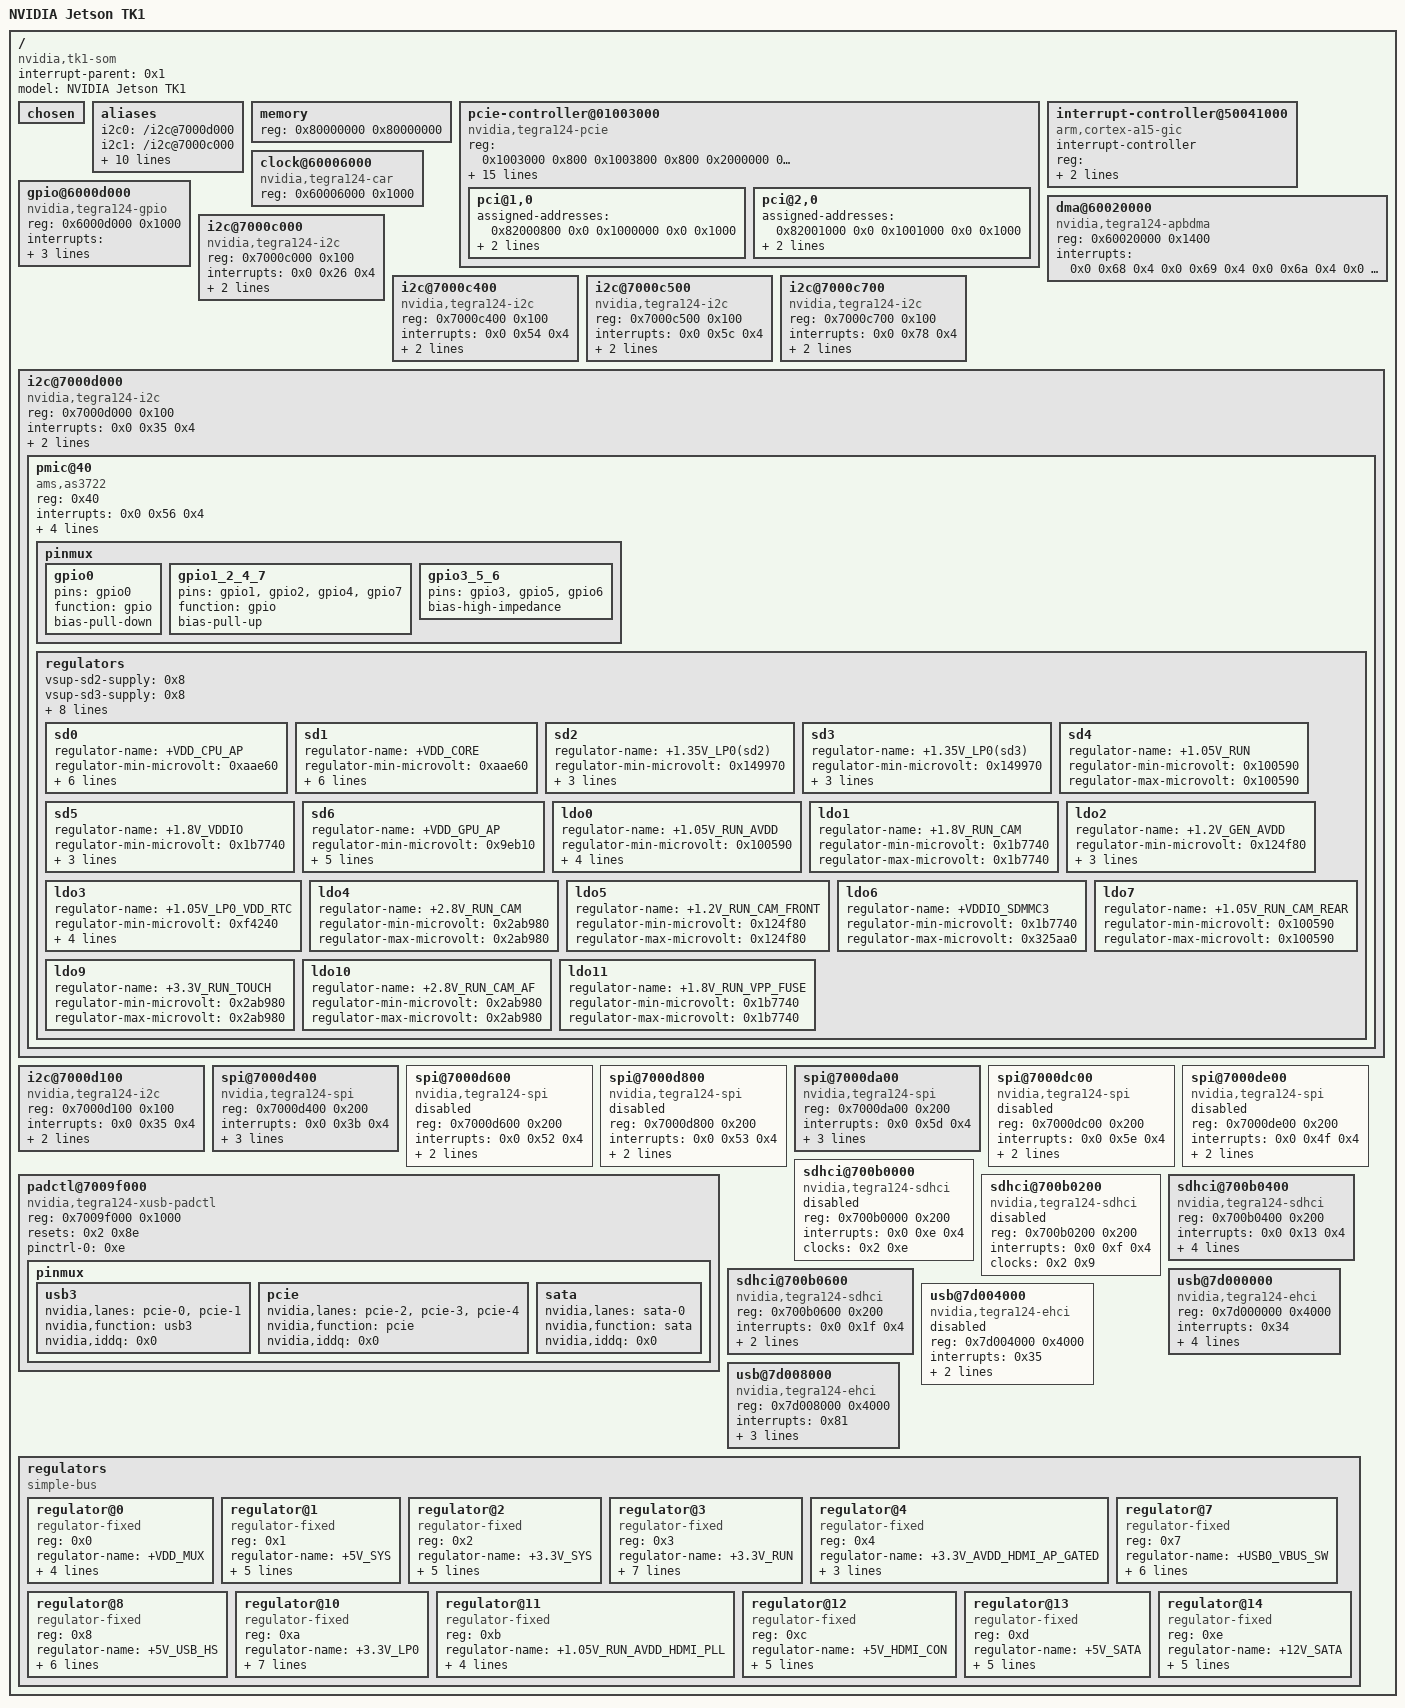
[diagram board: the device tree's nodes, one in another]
/dts-v1/;

/ {
	#address-cells = <0x1>;
	#size-cells = <0x1>;
	compatible = "nvidia,tk1-som", "nvidia,tegra124";
	interrupt-parent = <0x1>;
	model = "NVIDIA Jetson TK1";

	chosen {
	};

	aliases {
		i2c0 = "/i2c@7000d000";
		i2c1 = "/i2c@7000c000";
		i2c2 = "/i2c@7000c400";
		i2c3 = "/i2c@7000c500";
		i2c4 = "/i2c@7000c700";
		i2c5 = "/i2c@7000d100";
		sdhci0 = "/sdhci@700b0600";
		sdhci1 = "/sdhci@700b0400";
		spi0 = "/spi@7000d400";
		spi1 = "/spi@7000da00";
		usb0 = "/usb@7d000000";
		usb1 = "/usb@7d008000";
	};

	memory {
		device_type = "memory";
		reg = <0x80000000 0x80000000>;
	};

	pcie-controller@01003000 {
		compatible = "nvidia,tegra124-pcie";
		device_type = "pci";
		reg = <0x1003000 0x800 0x1003800 0x800 0x2000000 0x10000000>;
		reg-names = "pads", "afi", "cs";
		interrupts = <0x0 0x62 0x4 0x0 0x63 0x4>;
		interrupt-names = "intr", "msi";
		#interrupt-cells = <0x1>;
		interrupt-map-mask = <0x0 0x0 0x0 0x0>;
		interrupt-map = <0x0 0x0 0x0 0x0 0x1 0x0 0x62 0x4>;
		bus-range = <0x0 0xff>;
		#address-cells = <0x3>;
		#size-cells = <0x2>;
		ranges = <0x82000000 0x0 0x1000000 0x1000000 0x0 0x1000 0x82000000 0x0 0x1001000 0x1001000 0x0 0x1000 0x81000000 0x0 0x0 0x12000000 0x0 0x10000 0x82000000 0x0 0x13000000 0x13000000 0x0 0xd000000 0xc2000000 0x0 0x20000000 0x20000000 0x0 0x20000000>;
		clocks = <0x2 0x46 0x2 0x48 0x2 0xe7 0x2 0x10c>;
		clock-names = "pex", "afi", "pll_e", "cml";
		resets = <0x2 0x46 0x2 0x48 0x2 0x4a>;
		reset-names = "pex", "afi", "pcie_x";
		status = "okay";
		phys = <0x3 0x0>;
		phy-names = "pcie";
		avddio-pex-supply = <0x4>;
		vddio-pex-supply = <0x4>;
		avdd-pex-pll-supply = <0x4>;
		hvdd-pex-supply = <0x5>;
		hvdd-pex-plle-supply = <0x5>;
		vddio-pex-ctl-supply = <0x5>;
		avdd-plle-supply = <0x6>;

		pci@1,0 {
			device_type = "pci";
			assigned-addresses = <0x82000800 0x0 0x1000000 0x0 0x1000>;
			reg = <0x800 0x0 0x0 0x0 0x0>;
			status = "okay";
			#address-cells = <0x3>;
			#size-cells = <0x2>;
			ranges;
			nvidia,num-lanes = <0x4>;
		};

		pci@2,0 {
			device_type = "pci";
			assigned-addresses = <0x82001000 0x0 0x1001000 0x0 0x1000>;
			reg = <0x1000 0x0 0x0 0x0 0x0>;
			status = "okay";
			#address-cells = <0x3>;
			#size-cells = <0x2>;
			ranges;
			nvidia,num-lanes = <0x1>;
		};
	};

	interrupt-controller@50041000 {
		compatible = "arm,cortex-a15-gic";
		#interrupt-cells = <0x3>;
		interrupt-controller;
		reg = <0x50041000 0x1000 0x50042000 0x2000 0x50044000 0x2000 0x50046000 0x2000>;
		interrupts = <0x1 0x9 0xf04>;
		linux,phandle = <0x1>;
		phandle = <0x1>;
	};

	clock@60006000 {
		compatible = "nvidia,tegra124-car";
		reg = <0x60006000 0x1000>;
		#clock-cells = <0x1>;
		linux,phandle = <0x2>;
		phandle = <0x2>;
	};

	dma@60020000 {
		compatible = "nvidia,tegra124-apbdma", "nvidia,tegra148-apbdma";
		reg = <0x60020000 0x1400>;
		interrupts = <0x0 0x68 0x4 0x0 0x69 0x4 0x0 0x6a 0x4 0x0 0x6b 0x4 0x0 0x6c 0x4 0x0 0x6d 0x4 0x0 0x6e 0x4 0x0 0x6f 0x4 0x0 0x70 0x4 0x0 0x71 0x4 0x0 0x72 0x4 0x0 0x73 0x4 0x0 0x74 0x4 0x0 0x75 0x4 0x0 0x76 0x4 0x0 0x77 0x4 0x0 0x80 0x4 0x0 0x81 0x4 0x0 0x82 0x4 0x0 0x83 0x4 0x0 0x84 0x4 0x0 0x85 0x4 0x0 0x86 0x4 0x0 0x87 0x4 0x0 0x88 0x4 0x0 0x89 0x4 0x0 0x8a 0x4 0x0 0x8b 0x4 0x0 0x8c 0x4 0x0 0x8d 0x4 0x0 0x8e 0x4 0x0 0x8f 0x4>;
		linux,phandle = <0xd>;
		phandle = <0xd>;
	};

	gpio@6000d000 {
		compatible = "nvidia,tegra124-gpio", "nvidia,tegra30-gpio";
		reg = <0x6000d000 0x1000>;
		interrupts = <0x0 0x20 0x4 0x0 0x21 0x4 0x0 0x22 0x4 0x0 0x23 0x4 0x0 0x37 0x4 0x0 0x57 0x4 0x0 0x59 0x4 0x0 0x7d 0x4>;
		#gpio-cells = <0x2>;
		gpio-controller;
		#interrupt-cells = <0x2>;
		interrupt-controller;
		linux,phandle = <0xf>;
		phandle = <0xf>;
	};

	i2c@7000c000 {
		compatible = "nvidia,tegra124-i2c", "nvidia,tegra114-i2c";
		reg = <0x7000c000 0x100>;
		interrupts = <0x0 0x26 0x4>;
		#address-cells = <0x1>;
		#size-cells = <0x0>;
		clocks = <0x2 0xc>;
		status = "okay";
		clock-frequency = <0x186a0>;
	};

	i2c@7000c400 {
		compatible = "nvidia,tegra124-i2c", "nvidia,tegra114-i2c";
		reg = <0x7000c400 0x100>;
		interrupts = <0x0 0x54 0x4>;
		#address-cells = <0x1>;
		#size-cells = <0x0>;
		clocks = <0x2 0x36>;
		status = "okay";
		clock-frequency = <0x186a0>;
	};

	i2c@7000c500 {
		compatible = "nvidia,tegra124-i2c", "nvidia,tegra114-i2c";
		reg = <0x7000c500 0x100>;
		interrupts = <0x0 0x5c 0x4>;
		#address-cells = <0x1>;
		#size-cells = <0x0>;
		clocks = <0x2 0x43>;
		status = "okay";
		clock-frequency = <0x186a0>;
	};

	i2c@7000c700 {
		compatible = "nvidia,tegra124-i2c", "nvidia,tegra114-i2c";
		reg = <0x7000c700 0x100>;
		interrupts = <0x0 0x78 0x4>;
		#address-cells = <0x1>;
		#size-cells = <0x0>;
		clocks = <0x2 0x67>;
		status = "okay";
		clock-frequency = <0x186a0>;
	};

	i2c@7000d000 {
		compatible = "nvidia,tegra124-i2c", "nvidia,tegra114-i2c";
		reg = <0x7000d000 0x100>;
		interrupts = <0x0 0x35 0x4>;
		#address-cells = <0x1>;
		#size-cells = <0x0>;
		clocks = <0x2 0x2f>;
		status = "okay";
		clock-frequency = <0x61a80>;

		pmic@40 {
			compatible = "ams,as3722";
			reg = <0x40>;
			interrupts = <0x0 0x56 0x4>;
			ams,system-power-controller;
			#interrupt-cells = <0x2>;
			interrupt-controller;
			gpio-controller;
			#gpio-cells = <0x2>;
			pinctrl-names = "default";
			pinctrl-0 = <0x7>;
			linux,phandle = <0x11>;
			phandle = <0x11>;

			pinmux {
				linux,phandle = <0x7>;
				phandle = <0x7>;

				gpio0 {
					pins = "gpio0";
					function = "gpio";
					bias-pull-down;
				};

				gpio1_2_4_7 {
					pins = "gpio1", "gpio2", "gpio4", "gpio7";
					function = "gpio";
					bias-pull-up;
				};

				gpio3_5_6 {
					pins = "gpio3", "gpio5", "gpio6";
					bias-high-impedance;
				};
			};

			regulators {
				vsup-sd2-supply = <0x8>;
				vsup-sd3-supply = <0x8>;
				vsup-sd4-supply = <0x8>;
				vsup-sd5-supply = <0x8>;
				vin-ldo0-supply = <0x9>;
				vin-ldo1-6-supply = <0xa>;
				vin-ldo2-5-7-supply = <0xb>;
				vin-ldo3-4-supply = <0xc>;
				vin-ldo9-10-supply = <0x8>;
				vin-ldo11-supply = <0xa>;

				sd0 {
					regulator-name = "+VDD_CPU_AP";
					regulator-min-microvolt = <0xaae60>;
					regulator-max-microvolt = <0x155cc0>;
					regulator-min-microamp = <0x3567e0>;
					regulator-max-microamp = <0x3567e0>;
					regulator-always-on;
					regulator-boot-on;
					ams,ext-control = <0x2>;
				};

				sd1 {
					regulator-name = "+VDD_CORE";
					regulator-min-microvolt = <0xaae60>;
					regulator-max-microvolt = <0x149970>;
					regulator-min-microamp = <0x2625a0>;
					regulator-max-microamp = <0x2625a0>;
					regulator-always-on;
					regulator-boot-on;
					ams,ext-control = <0x1>;
				};

				sd2 {
					regulator-name = "+1.35V_LP0(sd2)";
					regulator-min-microvolt = <0x149970>;
					regulator-max-microvolt = <0x149970>;
					regulator-always-on;
					regulator-boot-on;
					linux,phandle = <0x9>;
					phandle = <0x9>;
				};

				sd3 {
					regulator-name = "+1.35V_LP0(sd3)";
					regulator-min-microvolt = <0x149970>;
					regulator-max-microvolt = <0x149970>;
					regulator-always-on;
					regulator-boot-on;
				};

				sd4 {
					regulator-name = "+1.05V_RUN";
					regulator-min-microvolt = <0x100590>;
					regulator-max-microvolt = <0x100590>;
					linux,phandle = <0x4>;
					phandle = <0x4>;
				};

				sd5 {
					regulator-name = "+1.8V_VDDIO";
					regulator-min-microvolt = <0x1b7740>;
					regulator-max-microvolt = <0x1b7740>;
					regulator-boot-on;
					regulator-always-on;
					linux,phandle = <0xb>;
					phandle = <0xb>;
				};

				sd6 {
					regulator-name = "+VDD_GPU_AP";
					regulator-min-microvolt = <0x9eb10>;
					regulator-max-microvolt = <0x124f80>;
					regulator-min-microamp = <0x3567e0>;
					regulator-max-microamp = <0x3567e0>;
					regulator-boot-on;
					regulator-always-on;
				};

				ldo0 {
					regulator-name = "+1.05V_RUN_AVDD";
					regulator-min-microvolt = <0x100590>;
					regulator-max-microvolt = <0x100590>;
					regulator-boot-on;
					regulator-always-on;
					ams,ext-control = <0x1>;
					linux,phandle = <0x6>;
					phandle = <0x6>;
				};

				ldo1 {
					regulator-name = "+1.8V_RUN_CAM";
					regulator-min-microvolt = <0x1b7740>;
					regulator-max-microvolt = <0x1b7740>;
				};

				ldo2 {
					regulator-name = "+1.2V_GEN_AVDD";
					regulator-min-microvolt = <0x124f80>;
					regulator-max-microvolt = <0x124f80>;
					regulator-boot-on;
					regulator-always-on;
				};

				ldo3 {
					regulator-name = "+1.05V_LP0_VDD_RTC";
					regulator-min-microvolt = <0xf4240>;
					regulator-max-microvolt = <0xf4240>;
					regulator-boot-on;
					regulator-always-on;
					ams,enable-tracking;
				};

				ldo4 {
					regulator-name = "+2.8V_RUN_CAM";
					regulator-min-microvolt = <0x2ab980>;
					regulator-max-microvolt = <0x2ab980>;
				};

				ldo5 {
					regulator-name = "+1.2V_RUN_CAM_FRONT";
					regulator-min-microvolt = <0x124f80>;
					regulator-max-microvolt = <0x124f80>;
				};

				ldo6 {
					regulator-name = "+VDDIO_SDMMC3";
					regulator-min-microvolt = <0x1b7740>;
					regulator-max-microvolt = <0x325aa0>;
				};

				ldo7 {
					regulator-name = "+1.05V_RUN_CAM_REAR";
					regulator-min-microvolt = <0x100590>;
					regulator-max-microvolt = <0x100590>;
				};

				ldo9 {
					regulator-name = "+3.3V_RUN_TOUCH";
					regulator-min-microvolt = <0x2ab980>;
					regulator-max-microvolt = <0x2ab980>;
				};

				ldo10 {
					regulator-name = "+2.8V_RUN_CAM_AF";
					regulator-min-microvolt = <0x2ab980>;
					regulator-max-microvolt = <0x2ab980>;
				};

				ldo11 {
					regulator-name = "+1.8V_RUN_VPP_FUSE";
					regulator-min-microvolt = <0x1b7740>;
					regulator-max-microvolt = <0x1b7740>;
				};
			};
		};
	};

	i2c@7000d100 {
		compatible = "nvidia,tegra124-i2c", "nvidia,tegra114-i2c";
		reg = <0x7000d100 0x100>;
		interrupts = <0x0 0x35 0x4>;
		#address-cells = <0x1>;
		#size-cells = <0x0>;
		clocks = <0x2 0x2f>;
		status = "okay";
		clock-frequency = <0x61a80>;
	};

	spi@7000d400 {
		compatible = "nvidia,tegra124-spi", "nvidia,tegra114-spi";
		reg = <0x7000d400 0x200>;
		interrupts = <0x0 0x3b 0x4>;
		nvidia,dma-request-selector = <0xd 0xf>;
		#address-cells = <0x1>;
		#size-cells = <0x0>;
		status = "okay";
		clocks = <0x2 0x29>;
		spi-max-frequency = <0x17d7840>;
	};

	spi@7000d600 {
		compatible = "nvidia,tegra124-spi", "nvidia,tegra114-spi";
		reg = <0x7000d600 0x200>;
		interrupts = <0x0 0x52 0x4>;
		nvidia,dma-request-selector = <0xd 0x10>;
		#address-cells = <0x1>;
		#size-cells = <0x0>;
		status = "disabled";
		clocks = <0x2 0x2c>;
	};

	spi@7000d800 {
		compatible = "nvidia,tegra124-spi", "nvidia,tegra114-spi";
		reg = <0x7000d800 0x200>;
		interrupts = <0x0 0x53 0x4>;
		nvidia,dma-request-selector = <0xd 0x11>;
		#address-cells = <0x1>;
		#size-cells = <0x0>;
		status = "disabled";
		clocks = <0x2 0x2e>;
	};

	spi@7000da00 {
		compatible = "nvidia,tegra124-spi", "nvidia,tegra114-spi";
		reg = <0x7000da00 0x200>;
		interrupts = <0x0 0x5d 0x4>;
		nvidia,dma-request-selector = <0xd 0x12>;
		#address-cells = <0x1>;
		#size-cells = <0x0>;
		status = "okay";
		clocks = <0x2 0x44>;
		spi-max-frequency = <0x17d7840>;
	};

	spi@7000dc00 {
		compatible = "nvidia,tegra124-spi", "nvidia,tegra114-spi";
		reg = <0x7000dc00 0x200>;
		interrupts = <0x0 0x5e 0x4>;
		nvidia,dma-request-selector = <0xd 0x1b>;
		#address-cells = <0x1>;
		#size-cells = <0x0>;
		status = "disabled";
		clocks = <0x2 0x68>;
	};

	spi@7000de00 {
		compatible = "nvidia,tegra124-spi", "nvidia,tegra114-spi";
		reg = <0x7000de00 0x200>;
		interrupts = <0x0 0x4f 0x4>;
		nvidia,dma-request-selector = <0xd 0x1c>;
		#address-cells = <0x1>;
		#size-cells = <0x0>;
		status = "disabled";
		clocks = <0x2 0x69>;
	};

	padctl@7009f000 {
		compatible = "nvidia,tegra124-xusb-padctl";
		reg = <0x7009f000 0x1000>;
		resets = <0x2 0x8e>;
		reset-names = "padctl";
		#phy-cells = <0x1>;
		pinctrl-0 = <0xe>;
		pinctrl-names = "default";
		linux,phandle = <0x3>;
		phandle = <0x3>;

		pinmux {
			linux,phandle = <0xe>;
			phandle = <0xe>;

			usb3 {
				nvidia,lanes = "pcie-0", "pcie-1";
				nvidia,function = "usb3";
				nvidia,iddq = <0x0>;
			};

			pcie {
				nvidia,lanes = "pcie-2", "pcie-3", "pcie-4";
				nvidia,function = "pcie";
				nvidia,iddq = <0x0>;
			};

			sata {
				nvidia,lanes = "sata-0";
				nvidia,function = "sata";
				nvidia,iddq = <0x0>;
			};
		};
	};

	sdhci@700b0000 {
		compatible = "nvidia,tegra124-sdhci";
		reg = <0x700b0000 0x200>;
		interrupts = <0x0 0xe 0x4>;
		clocks = <0x2 0xe>;
		status = "disabled";
	};

	sdhci@700b0200 {
		compatible = "nvidia,tegra124-sdhci";
		reg = <0x700b0200 0x200>;
		interrupts = <0x0 0xf 0x4>;
		clocks = <0x2 0x9>;
		status = "disabled";
	};

	sdhci@700b0400 {
		compatible = "nvidia,tegra124-sdhci";
		reg = <0x700b0400 0x200>;
		interrupts = <0x0 0x13 0x4>;
		clocks = <0x2 0x45>;
		status = "okay";
		cd-gpios = <0xf 0xaa 0x1>;
		power-gpios = <0xf 0x88 0x0>;
		bus-width = <0x4>;
	};

	sdhci@700b0600 {
		compatible = "nvidia,tegra124-sdhci";
		reg = <0x700b0600 0x200>;
		interrupts = <0x0 0x1f 0x4>;
		clocks = <0x2 0xf>;
		status = "okay";
		bus-width = <0x8>;
	};

	usb@7d000000 {
		compatible = "nvidia,tegra124-ehci", "nvidia,tegra30-ehci";
		reg = <0x7d000000 0x4000>;
		interrupts = <0x34>;
		phy_type = "utmi";
		clocks = <0x2 0x16>;
		status = "okay";
		dr_mode = "otg";
		nvidia,vbus-gpio = <0xf 0x6c 0x0>;
	};

	usb@7d004000 {
		compatible = "nvidia,tegra124-ehci", "nvidia,tegra30-ehci";
		reg = <0x7d004000 0x4000>;
		interrupts = <0x35>;
		phy_type = "hsic";
		clocks = <0x2 0x3a>;
		status = "disabled";
	};

	usb@7d008000 {
		compatible = "nvidia,tegra124-ehci", "nvidia,tegra30-ehci";
		reg = <0x7d008000 0x4000>;
		interrupts = <0x81>;
		phy_type = "utmi";
		clocks = <0x2 0x3b>;
		status = "okay";
		nvidia,vbus-gpio = <0xf 0x6d 0x0>;
	};

	regulators {
		compatible = "simple-bus";
		#address-cells = <0x1>;
		#size-cells = <0x0>;

		regulator@0 {
			compatible = "regulator-fixed";
			reg = <0x0>;
			regulator-name = "+VDD_MUX";
			regulator-min-microvolt = <0xb71b00>;
			regulator-max-microvolt = <0xb71b00>;
			regulator-always-on;
			regulator-boot-on;
			linux,phandle = <0x10>;
			phandle = <0x10>;
		};

		regulator@1 {
			compatible = "regulator-fixed";
			reg = <0x1>;
			regulator-name = "+5V_SYS";
			regulator-min-microvolt = <0x4c4b40>;
			regulator-max-microvolt = <0x4c4b40>;
			regulator-always-on;
			regulator-boot-on;
			vin-supply = <0x10>;
			linux,phandle = <0x8>;
			phandle = <0x8>;
		};

		regulator@2 {
			compatible = "regulator-fixed";
			reg = <0x2>;
			regulator-name = "+3.3V_SYS";
			regulator-min-microvolt = <0x325aa0>;
			regulator-max-microvolt = <0x325aa0>;
			regulator-always-on;
			regulator-boot-on;
			vin-supply = <0x10>;
			linux,phandle = <0xc>;
			phandle = <0xc>;
		};

		regulator@3 {
			compatible = "regulator-fixed";
			reg = <0x3>;
			regulator-name = "+3.3V_RUN";
			regulator-min-microvolt = <0x325aa0>;
			regulator-max-microvolt = <0x325aa0>;
			regulator-always-on;
			regulator-boot-on;
			gpio = <0x11 0x1 0x0>;
			enable-active-high;
			vin-supply = <0xc>;
			linux,phandle = <0xa>;
			phandle = <0xa>;
		};

		regulator@4 {
			compatible = "regulator-fixed";
			reg = <0x4>;
			regulator-name = "+3.3V_AVDD_HDMI_AP_GATED";
			regulator-min-microvolt = <0x325aa0>;
			regulator-max-microvolt = <0x325aa0>;
			vin-supply = <0xa>;
		};

		regulator@7 {
			compatible = "regulator-fixed";
			reg = <0x7>;
			regulator-name = "+USB0_VBUS_SW";
			regulator-min-microvolt = <0x4c4b40>;
			regulator-max-microvolt = <0x4c4b40>;
			gpio = <0xf 0x6c 0x0>;
			enable-active-high;
			gpio-open-drain;
			vin-supply = <0x8>;
		};

		regulator@8 {
			compatible = "regulator-fixed";
			reg = <0x8>;
			regulator-name = "+5V_USB_HS";
			regulator-min-microvolt = <0x4c4b40>;
			regulator-max-microvolt = <0x4c4b40>;
			gpio = <0xf 0x6d 0x0>;
			enable-active-high;
			gpio-open-drain;
			vin-supply = <0x8>;
		};

		regulator@10 {
			compatible = "regulator-fixed";
			reg = <0xa>;
			regulator-name = "+3.3V_LP0";
			regulator-min-microvolt = <0x325aa0>;
			regulator-max-microvolt = <0x325aa0>;
			regulator-always-on;
			regulator-boot-on;
			gpio = <0x11 0x2 0x0>;
			enable-active-high;
			vin-supply = <0xc>;
			linux,phandle = <0x5>;
			phandle = <0x5>;
		};

		regulator@11 {
			compatible = "regulator-fixed";
			reg = <0xb>;
			regulator-name = "+1.05V_RUN_AVDD_HDMI_PLL";
			regulator-min-microvolt = <0x100590>;
			regulator-max-microvolt = <0x100590>;
			gpio = <0xf 0x3f 0x1>;
			vin-supply = <0x4>;
		};

		regulator@12 {
			compatible = "regulator-fixed";
			reg = <0xc>;
			regulator-name = "+5V_HDMI_CON";
			regulator-min-microvolt = <0x4c4b40>;
			regulator-max-microvolt = <0x4c4b40>;
			gpio = <0xf 0x56 0x0>;
			enable-active-high;
			vin-supply = <0x8>;
		};

		regulator@13 {
			compatible = "regulator-fixed";
			reg = <0xd>;
			regulator-name = "+5V_SATA";
			regulator-min-microvolt = <0x4c4b40>;
			regulator-max-microvolt = <0x4c4b40>;
			gpio = <0xf 0xf2 0x0>;
			enable-active-high;
			vin-supply = <0x8>;
		};

		regulator@14 {
			compatible = "regulator-fixed";
			reg = <0xe>;
			regulator-name = "+12V_SATA";
			regulator-min-microvolt = <0xb71b00>;
			regulator-max-microvolt = <0xb71b00>;
			gpio = <0xf 0xf2 0x0>;
			enable-active-high;
			vin-supply = <0x10>;
		};
	};
};
